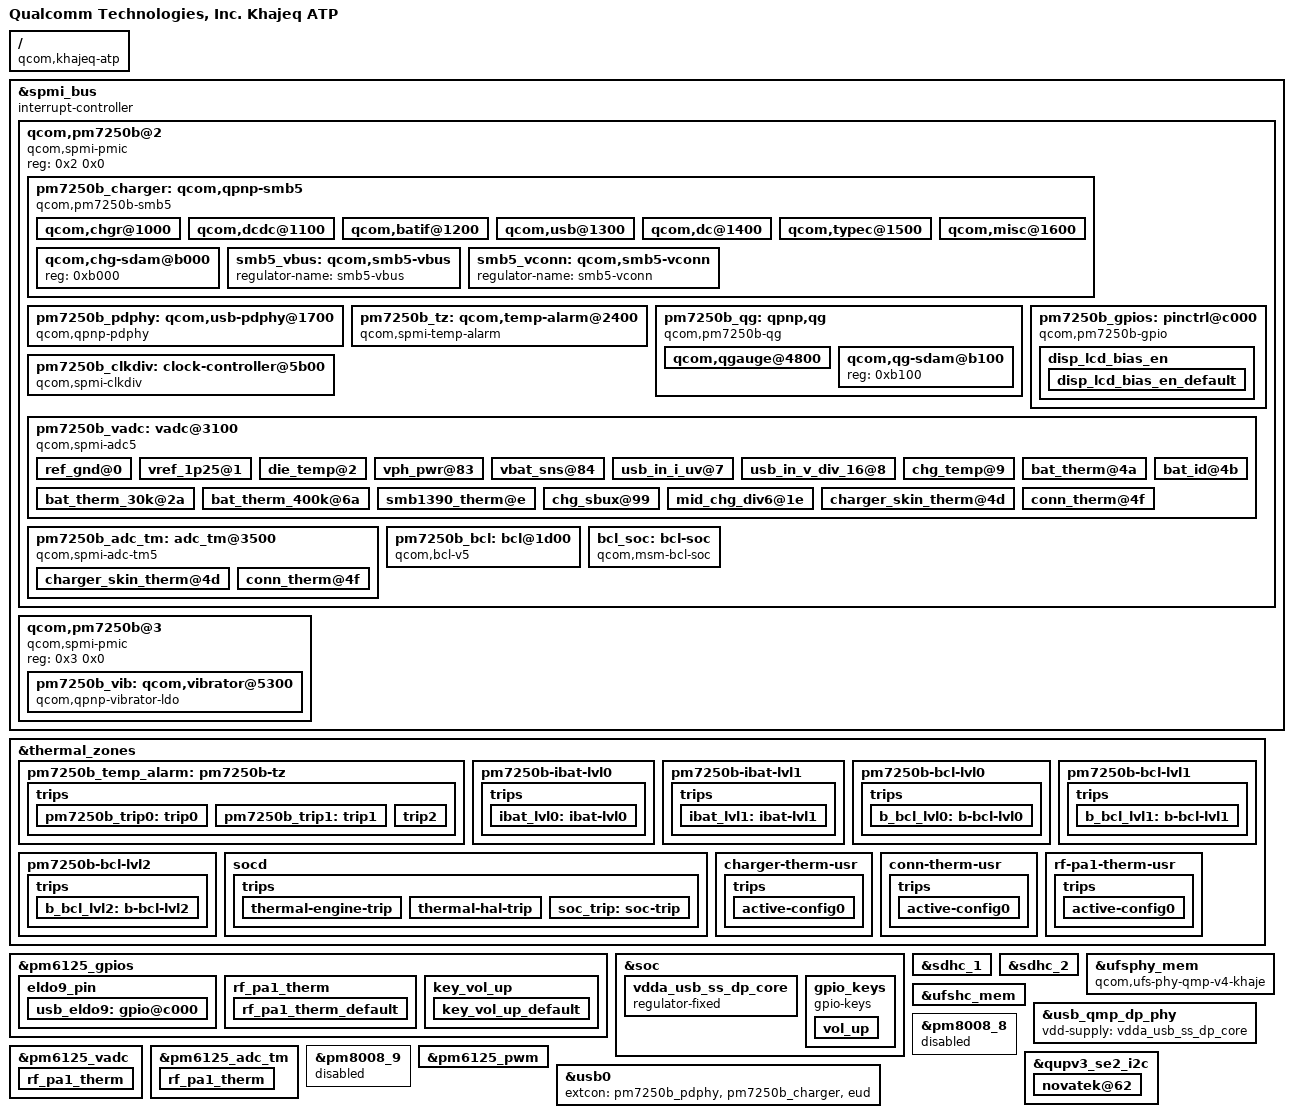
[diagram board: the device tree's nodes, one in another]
// SPDX-License-Identifier: GPL-2.0-only
/*
 * Stock dtbo.img entry 35: Qualcomm Technologies, Inc. Khajeq ATP
 * Kernel board overlay part, reconstructed from the stock image
 * (Qualcomm reference board as built in the Xiaomi sapphire tree).
 */

/dts-v1/;
/plugin/;

/ {
	model = "Qualcomm Technologies, Inc. Khajeq ATP";
	compatible = "qcom,khajeq-atp", "qcom,khajeq", "qcom,atp";
	qcom,msm-id = <0x232 0x10000>;
	qcom,board-id = <0x21 0x0>;
	qcom,pmic-id = <0x2d 0x2e 0x0 0x0>;
};

#include <dt-bindings/clock/qcom,gcc-khaje.h>
#include <dt-bindings/clock/qcom,rpmcc.h>

&spmi_bus {
	#address-cells = <2>;
	#size-cells = <0>;
	interrupt-controller;
	#interrupt-cells = <4>;

	qcom,pm7250b@2 {
		compatible = "qcom,spmi-pmic";
		reg = <0x2 0x0>;
		#address-cells = <1>;
		#size-cells = <0>;

		pm7250b_charger: qcom,qpnp-smb5 {
			compatible = "qcom,pm7250b-smb5";
			depends-on-supply = <&pm7250b_vadc>;
			#address-cells = <1>;
			#size-cells = <1>;
			#cooling-cells = <2>;
			qcom,thermal-mitigation = <5950000 5400000 5000000 4500000 4000000 3700000 3500000 3000000
			                           2800000 2500000 2000000 1500000 1000000 800000 500000 350000
			                           800000 800000>;
			qcom,hvdcp2-max-icl-ua = <2000000>;
			qcom,hvdcp2-12v-max-icl-ua = <1500000>;
			status = "ok";
			io-channels = <&pm7250b_vadc 8 &pm7250b_vadc 7
			               &pm7250b_vadc 9 &pm7250b_vadc 6
			               &pm7250b_vadc 79 &pm7250b_vadc 153
			               &pm7250b_vadc 131>;
			io-channel-names = "usb_in_voltage", "usb_in_current", "chg_temp", "die_temp", "conn_temp", "sbux_res", "vph_voltage";
			qcom,batteryless-platform;
			qcom,sec-charger-config = <0>;
			qcom,auto-recharge-soc = <98>;
			qcom,step-charging-enable;
			qcom,sw-jeita-enable;
			qcom,charger-temp-max = <800>;
			qcom,suspend-input-on-debug-batt;
			dpdm-supply = <&usb2_phy0>;

			qcom,chgr@1000 {
				reg = <0x1000>;
				interrupts = <2 16 0 1 2 16 1 1
				              2 16 2 1 2 16 3 1
				              2 16 4 1 2 16 5 1
				              2 16 6 1 2 16 7 1>;
				interrupt-names = "chgr-error", "chg-state-change", "step-chg-state-change", "step-chg-soc-update-fail", "step-chg-soc-update-req", "fg-fvcal-qualified", "vph-alarm", "vph-drop-prechg";
			};

			qcom,dcdc@1100 {
				reg = <0x1100>;
				interrupts = <2 17 0 1 2 17 1 1
				              2 17 2 1 2 17 3 3
				              2 17 4 3 2 17 5 3
				              2 17 6 1 2 17 7 3>;
				interrupt-names = "otg-fail", "otg-oc-disable-sw", "otg-oc-hiccup", "bsm-active", "high-duty-cycle", "input-current-limiting", "concurrent-mode-disable", "switcher-power-ok";
			};

			qcom,batif@1200 {
				reg = <0x1200>;
				interrupts = <2 18 0 1 2 18 2 3
				              2 18 3 3 2 18 4 3
				              2 18 5 3 2 18 6 3
				              2 18 7 3>;
				interrupt-names = "bat-temp", "bat-ov", "bat-low", "bat-therm-or-id-missing", "bat-terminal-missing", "buck-oc", "vph-ov";
			};

			qcom,usb@1300 {
				reg = <0x1300>;
				interrupts = <2 19 0 3 2 19 1 3
				              2 19 2 3 2 19 3 3
				              2 19 4 3 2 19 5 3
				              2 19 6 1 2 19 7 1>;
				interrupt-names = "usbin-collapse", "usbin-vashdn", "usbin-uv", "usbin-ov", "usbin-plugin", "usbin-revi-change", "usbin-src-change", "usbin-icl-change";
			};

			qcom,dc@1400 {
				reg = <0x1400>;
				interrupts = <2 20 1 3 2 20 2 3
				              2 20 3 3 2 20 4 3
				              2 20 5 3 2 20 6 1
				              2 20 7 1>;
				interrupt-names = "dcin-vashdn", "dcin-uv", "dcin-ov", "dcin-plugin", "dcin-revi", "dcin-pon", "dcin-en";
			};

			qcom,typec@1500 {
				reg = <0x1500>;
				interrupts = <2 21 0 1 2 21 1 1
				              2 21 2 1 2 21 3 1
				              2 21 4 1 2 21 5 1
				              2 21 6 1 2 21 7 1>;
				interrupt-names = "typec-or-rid-detect-change", "typec-vpd-detect", "typec-cc-state-change", "typec-vconn-oc", "typec-vbus-change", "typec-attach-detach", "typec-legacy-cable-detect", "typec-try-snk-src-detect";
			};

			qcom,misc@1600 {
				reg = <0x1600>;
				interrupts = <2 22 0 1 2 22 1 1
				              2 22 2 1 2 22 3 1
				              2 22 4 3 2 22 5 1
				              2 22 6 1 2 22 7 1>;
				interrupt-names = "wdog-snarl", "wdog-bark", "aicl-fail", "aicl-done", "smb-en", "imp-trigger", "temp-change", "temp-change-smb";
			};

			qcom,chg-sdam@b000 {
				reg = <0xb000>;
			};

			smb5_vbus: qcom,smb5-vbus {
				regulator-name = "smb5-vbus";
			};

			smb5_vconn: qcom,smb5-vconn {
				regulator-name = "smb5-vconn";
			};
		};

		pm7250b_pdphy: qcom,usb-pdphy@1700 {
			compatible = "qcom,qpnp-pdphy";
			reg = <0x1700>;
			interrupts = <2 23 0 1 2 23 1 1
			              2 23 2 1 2 23 3 1
			              2 23 4 1 2 23 5 1
			              2 23 6 1 2 23 7 1>;
			interrupt-names = "sig-tx", "sig-rx", "msg-tx", "msg-rx", "msg-tx-failed", "msg-tx-discarded", "msg-rx-discarded", "fr-swap";
			#io-channel-cells = <1>;
			qcom,default-sink-caps = <5000 3000 9000 3000 12000 2250>;
			vdd-pdphy-supply = <&L15A>;
			vbus-supply = <&smb5_vbus>;
			vconn-supply = <&smb5_vconn>;
		};

		pm7250b_tz: qcom,temp-alarm@2400 {
			compatible = "qcom,spmi-temp-alarm";
			reg = <0x2400>;
			interrupts = <2 36 0 3>;
			io-channels = <&pm7250b_vadc 6>;
			io-channel-names = "thermal";
			#thermal-sensor-cells = <0>;
			qcom,temperature-threshold-set = <1>;
		};

		pm7250b_qg: qpnp,qg {
			compatible = "qcom,pm7250b-qg";
			depends-on-supply = <&pm6125_rtc>;
			#address-cells = <1>;
			#size-cells = <1>;
			qcom,vbatt-cutoff-mv = <3200>;
			qcom,vbatt-low-mv = <3300>;
			qcom,vbatt-low-cold-mv = <3700>;
			qcom,vbatt-empty-mv = <3000>;
			qcom,vbatt-empty-cold-mv = <3000>;
			qcom,s3-entry-fifo-length = <2>;
			qcom,soc_decimal_rate = <0 32 10 30 20 28 30 28
			                         40 28 50 28 60 28 70 28
			                         80 28 90 26 95 10 99 5>;
			status = "ok";
			io-channels = <&pm7250b_vadc 42 &pm7250b_vadc 75>;
			io-channel-names = "batt-therm", "batt-id";
			qcom,qg-iterm-ma = <150>;
			qcom,hold-soc-while-full;
			qcom,linearize-soc;
			qcom,cl-feedback-on;

			qcom,qgauge@4800 {
				status = "okay";
				reg = <0x4800>;
				interrupts = <2 72 0 3 2 72 1 3
				              2 72 2 1 2 72 3 1
				              2 72 4 1>;
				interrupt-names = "qg-batt-missing", "qg-vbat-low", "qg-vbat-empty", "qg-fifo-done", "qg-good-ocv";
			};

			qcom,qg-sdam@b100 {
				status = "okay";
				reg = <0xb100>;
			};
		};

		pm7250b_clkdiv: clock-controller@5b00 {
			compatible = "qcom,spmi-clkdiv";
			reg = <0x5b00>;
			#clock-cells = <1>;
			qcom,num-clkdivs = <1>;
			clock-output-names = "pm7250b_div_clk1";
			clocks = <&rpmcc RPM_PXO_CLK>;
			clock-names = "xo";
			assigned-clocks = <&pm7250b_clkdiv 1>;
			assigned-clock-rates = <19200000>;
		};

		pm7250b_gpios: pinctrl@c000 {
			compatible = "qcom,pm7250b-gpio";
			reg = <0xc000>;
			gpio-controller;
			#gpio-cells = <2>;
			interrupt-controller;
			#interrupt-cells = <2>;

			disp_lcd_bias_en {
				disp_lcd_bias_en_default: disp_lcd_bias_en_default {
					pins = "gpio5";
					function = "func1";
					input-disable;
					output-enable;
					bias-disable;
					power-source = <0>;
					qcom,drive-strength = <2>;
				};
			};
		};

		pm7250b_vadc: vadc@3100 {
			compatible = "qcom,spmi-adc5";
			reg = <0x3100>;
			reg-names = "adc5-usr-base";
			#address-cells = <1>;
			#size-cells = <0>;
			interrupts = <2 49 0 1>;
			interrupt-names = "eoc-int-en-set";
			qcom,adc-vdd-reference = <1875>;
			#io-channel-cells = <1>;
			io-channel-ranges;

			ref_gnd@0 {
				reg = <0x0>;
				label = "ref_gnd";
				qcom,pre-scaling = <1 1>;
			};

			vref_1p25@1 {
				reg = <0x1>;
				label = "vref_1p25";
				qcom,pre-scaling = <1 1>;
			};

			die_temp@2 {
				reg = <0x6>;
				label = "die_temp";
				qcom,pre-scaling = <1 1>;
			};

			vph_pwr@83 {
				reg = <0x83>;
				label = "vph_pwr";
				qcom,pre-scaling = <1 3>;
			};

			vbat_sns@84 {
				reg = <0x84>;
				label = "vbat_sns";
				qcom,pre-scaling = <1 3>;
			};

			usb_in_i_uv@7 {
				reg = <0x7>;
				label = "usb_in_i_uv";
				qcom,pre-scaling = <1 1>;
			};

			usb_in_v_div_16@8 {
				reg = <0x8>;
				label = "usb_in_v_div_16";
				qcom,pre-scaling = <1 16>;
			};

			chg_temp@9 {
				reg = <0x9>;
				label = "chg_temp";
				qcom,pre-scaling = <1 1>;
			};

			bat_therm@4a {
				reg = <0x4a>;
				label = "bat_therm";
				qcom,ratiometric;
				qcom,hw-settle-time = <200>;
				qcom,pre-scaling = <1 1>;
			};

			bat_therm_30k@2a {
				reg = <0x2a>;
				label = "bat_therm_30k";
				qcom,ratiometric;
				qcom,hw-settle-time = <200>;
				qcom,pre-scaling = <1 1>;
			};

			bat_therm_400k@6a {
				reg = <0x6a>;
				label = "bat_therm_400k";
				qcom,ratiometric;
				qcom,hw-settle-time = <200>;
				qcom,pre-scaling = <1 1>;
			};

			bat_id@4b {
				reg = <0x4b>;
				label = "bat_id";
				qcom,ratiometric;
				qcom,hw-settle-time = <200>;
				qcom,pre-scaling = <1 1>;
			};

			smb1390_therm@e {
				reg = <0xe>;
				label = "smb1390_therm";
				qcom,hw-settle-time = <200>;
				qcom,pre-scaling = <1 1>;
			};

			chg_sbux@99 {
				reg = <0x99>;
				label = "chg_sbux";
				qcom,pre-scaling = <1 3>;
			};

			mid_chg_div6@1e {
				reg = <0x1e>;
				label = "chg_mid";
				qcom,pre-scaling = <1 6>;
			};

			charger_skin_therm@4d {
				reg = <0x4d>;
				label = "charger_skin_therm";
				qcom,ratiometric;
				qcom,hw-settle-time = <200>;
				qcom,pre-scaling = <1 1>;
			};

			conn_therm@4f {
				reg = <0x4f>;
				label = "conn_therm";
				qcom,ratiometric;
				qcom,hw-settle-time = <200>;
				qcom,pre-scaling = <1 1>;
			};
		};

		pm7250b_adc_tm: adc_tm@3500 {
			compatible = "qcom,spmi-adc-tm5";
			reg = <0x3500>;
			interrupts = <2 53 0 1>;
			interrupt-names = "pm-adc-tm5";
			#address-cells = <1>;
			#size-cells = <0>;
			#thermal-sensor-cells = <1>;
			status = "ok";

			charger_skin_therm@4d {
				reg = <0x0>;
				io-channels = <&pm7250b_vadc 77>;
				qcom,ratiometric;
				qcom,hw-settle-time-us = <200>;
			};

			conn_therm@4f {
				reg = <0x1>;
				io-channels = <&pm7250b_vadc 79>;
				qcom,ratiometric;
				qcom,hw-settle-time-us = <200>;
			};
		};

		pm7250b_bcl: bcl@1d00 {
			compatible = "qcom,bcl-v5";
			reg = <0x1d00>;
			interrupts = <2 29 0 0 2 29
			              1 0 2 29 2 0>;
			interrupt-names = "bcl-lvl0", "bcl-lvl1", "bcl-lvl2";
			#thermal-sensor-cells = <1>;
		};

		bcl_soc: bcl-soc {
			compatible = "qcom,msm-bcl-soc";
			#thermal-sensor-cells = <0>;
		};
	};

	qcom,pm7250b@3 {
		compatible = "qcom,spmi-pmic";
		reg = <0x3 0x0>;
		#address-cells = <1>;
		#size-cells = <0>;

		pm7250b_vib: qcom,vibrator@5300 {
			compatible = "qcom,qpnp-vibrator-ldo";
			reg = <0x5300>;
			qcom,vib-ldo-volt-uv = <3000000>;
			qcom,disable-overdrive;
		};
	};
};

&thermal_zones {
	pm7250b_temp_alarm: pm7250b-tz {
		polling-delay-passive = <100>;
		polling-delay = <0>;
		thermal-sensors = <&pm7250b_tz>;

		trips {
			pm7250b_trip0: trip0 {
				temperature = <95000>;
				hysteresis = <0>;
				type = "passive";
			};

			pm7250b_trip1: trip1 {
				temperature = <115000>;
				hysteresis = <0>;
				type = "passive";
			};

			trip2 {
				temperature = <145000>;
				hysteresis = <0>;
				type = "passive";
			};
		};
	};

	pm7250b-ibat-lvl0 {
		polling-delay-passive = <0>;
		polling-delay = <0>;
		thermal-sensors = <&pm7250b_bcl 0>;

		trips {
			ibat_lvl0: ibat-lvl0 {
				temperature = <5500>;
				hysteresis = <200>;
				type = "passive";
			};
		};
	};

	pm7250b-ibat-lvl1 {
		polling-delay-passive = <0>;
		polling-delay = <0>;
		thermal-sensors = <&pm7250b_bcl 1>;

		trips {
			ibat_lvl1: ibat-lvl1 {
				temperature = <6000>;
				hysteresis = <200>;
				type = "passive";
			};
		};
	};

	pm7250b-bcl-lvl0 {
		polling-delay-passive = <100>;
		polling-delay = <0>;
		thermal-sensors = <&pm7250b_bcl 5>;

		trips {
			b_bcl_lvl0: b-bcl-lvl0 {
				temperature = <1>;
				hysteresis = <1>;
				type = "passive";
			};
		};
	};

	pm7250b-bcl-lvl1 {
		polling-delay-passive = <100>;
		polling-delay = <0>;
		thermal-sensors = <&pm7250b_bcl 6>;

		trips {
			b_bcl_lvl1: b-bcl-lvl1 {
				temperature = <1>;
				hysteresis = <1>;
				type = "passive";
			};
		};
	};

	pm7250b-bcl-lvl2 {
		polling-delay-passive = <100>;
		polling-delay = <0>;
		thermal-sensors = <&pm7250b_bcl 7>;

		trips {
			b_bcl_lvl2: b-bcl-lvl2 {
				temperature = <1>;
				hysteresis = <1>;
				type = "passive";
			};
		};
	};

	socd {
		polling-delay-passive = <100>;
		polling-delay = <0>;

		trips {
			thermal-engine-trip {
				temperature = <100>;
				hysteresis = <0>;
				type = "passive";
			};

			thermal-hal-trip {
				temperature = <100>;
				hysteresis = <0>;
				type = "passive";
			};

			soc_trip: soc-trip {
				temperature = <90>;
				hysteresis = <0>;
				type = "passive";
			};
		};
	};
};

&thermal_zones {
	charger-therm-usr {
		polling-delay-passive = <0>;
		polling-delay = <0>;
		thermal-governor = "user_space";
		thermal-sensors = <&pm7250b_adc_tm 0>;
		wake-capable-sensor;

		trips {
			active-config0 {
				temperature = <125000>;
				hysteresis = <1000>;
				type = "passive";
			};
		};
	};

	conn-therm-usr {
		polling-delay-passive = <0>;
		polling-delay = <0>;
		thermal-governor = "user_space";
		thermal-sensors = <&pm7250b_adc_tm 1>;
		wake-capable-sensor;

		trips {
			active-config0 {
				temperature = <125000>;
				hysteresis = <1000>;
				type = "passive";
			};
		};
	};
};

&pm6125_gpios {
	eldo9_pin {
		usb_eldo9: gpio@c000 {
			pins = "gpio1";
			function = "normal";
			qcom,drive-strength = <2>;
			power-source = <0>;
			bias-disable;
			output-high;
		};
	};
};

&soc {
	vdda_usb_ss_dp_core: vdda_usb_ss_dp_core {
		compatible = "regulator-fixed";
		regulator-name = "vdd_supply";
		regulator-min-microvolt = <880000>;
		regulator-max-microvolt = <880000>;
		enable-active-high;
		gpio = <&pm6125_gpios 1 0>;
		pinctrl-names = "default";
		pinctrl-0 = <&usb_eldo9>;
	};
};

&sdhc_1 {
	vdd-supply = <&L24A>;
	qcom,vdd-voltage-level = <2960000 2960000>;
	qcom,vdd-current-level = <0 570000>;
	vdd-io-supply = <&L11A>;
	qcom,vdd-io-always-on;
	qcom,vdd-io-lpm-sup;
	qcom,vdd-io-voltage-level = <1800000 1800000>;
	qcom,vdd-io-current-level = <0 325000>;
	pinctrl-names = "active", "sleep";
	pinctrl-0 = <&sdc1_on>;
	pinctrl-1 = <&sdc1_off>;
	status = "ok";
};

&sdhc_2 {
	vdd-supply = <&L22A>;
	qcom,vdd-voltage-level = <2960000 2960000>;
	qcom,vdd-current-level = <0 800000>;
	vdd-io-supply = <&L5A>;
	qcom,vdd-io-voltage-level = <1800000 2960000>;
	qcom,vdd-io-current-level = <0 22000>;
	vdd-io-bias-supply = <&L7A>;
	qcom,vdd-io-bias-voltage-level = <1256000 1256000>;
	qcom,vdd-io-bias-current-level = <0 6000>;
	pinctrl-names = "active", "sleep";
	pinctrl-0 = <&sdc2_on>;
	pinctrl-1 = <&sdc2_off>;
	cd-gpios = <&tlmm 88 1>;
	status = "ok";
};

&ufsphy_mem {
	compatible = "qcom,ufs-phy-qmp-v4-khaje";
	vdda-phy-supply = <&L4A>;
	vdda-pll-supply = <&L18A>;
	vdda-phy-max-microamp = <85700>;
	vdda-pll-max-microamp = <18300>;
	status = "ok";
};

&ufshc_mem {
	vdd-hba-supply = <&gcc_ufs_phy_gdsc>;
	vdd-hba-fixed-regulator;
	vcc-supply = <&L24A>;
	vcc-max-microamp = <800000>;
	vccq2-supply = <&L11A>;
	vccq2-max-microamp = <800000>;
	qcom,vddp-ref-clk-supply = <&L18A>;
	qcom,vddp-ref-clk-max-microamp = <100>;
	reset-gpios = <&tlmm 113 1>;
	resets = <&gcc GCC_UFS_PHY_BCR>;
	reset-names = "rst";
	status = "ok";
};

&usb_qmp_dp_phy {
	vdd-supply = <&vdda_usb_ss_dp_core>;
};

&pm6125_vadc {
	pinctrl-0 = <&camera_therm_default &emmc_therm_default &rf_pa1_therm_default>;

	rf_pa1_therm {
		reg = <0x55>;
		label = "rf_pa1_therm";
		qcom,ratiometric;
		qcom,hw-settle-time = <200>;
		qcom,pre-scaling = <1 1>;
	};
};

&pm6125_adc_tm {
	status = "ok";

	rf_pa1_therm {
		reg = <0x3>;
		io-channels = <&pm6125_vadc 85>;
		qcom,ratiometric;
		qcom,hw-settle-time-us = <200>;
	};
};

&thermal_zones {
	rf-pa1-therm-usr {
		polling-delay-passive = <0>;
		polling-delay = <0>;
		thermal-governor = "user_space";
		thermal-sensors = <&pm6125_adc_tm 3>;
		wake-capable-sensor;

		trips {
			active-config0 {
				temperature = <125000>;
				hysteresis = <1000>;
				type = "passive";
			};
		};
	};
};

&pm6125_gpios {
	rf_pa1_therm {
		rf_pa1_therm_default: rf_pa1_therm_default {
			pins = "gpio7";
			bias-high-impedance;
		};
	};

	key_vol_up {
		key_vol_up_default: key_vol_up_default {
			pins = "gpio5";
			function = "normal";
			input-enable;
			bias-pull-up;
			power-source = <0>;
		};
	};
};

&soc {
	gpio_keys {
		compatible = "gpio-keys";
		label = "gpio-keys";
		pinctrl-names = "default";
		pinctrl-0 = <&key_vol_up_default>;

		vol_up {
			label = "volume_up";
			gpios = <&pm6125_gpios 5 1>;
			linux,input-type = <1>;
			linux,code = <115>;
			linux,can-disable;
			debounce-interval = <15>;
			gpio-key,wakeup;
		};
	};
};

&pm8008_8 {
	status = "disabled";
};

&pm8008_9 {
	status = "disabled";
};

&pm6125_pwm {
	status = "okay";
};

&qupv3_se2_i2c {
	status = "okay";

	novatek@62 {
		reg = <0x62>;
		status = "ok";
		interrupt-parent = <&tlmm>;
		interrupts = <80 8200>;
		pinctrl-names = "pmx_ts_active", "pmx_ts_suspend", "pmx_ts_release";
		pinctrl-0 = <&ts_int_active &ts_reset_active>;
		pinctrl-1 = <&ts_int_suspend &ts_reset_suspend>;
		pinctrl-2 = <&ts_release>;
		novatek,reset-gpio = <&tlmm 86 0>;
		novatek,irq-gpio = <&tlmm 80 8200>;
	};
};

&usb0 {
	extcon = <&pm7250b_pdphy &pm7250b_charger &eud>;
};
